VERSION ""

NS_ :

BS_:

BU_: DBG MASTER GPS MOTOR SENSOR APP

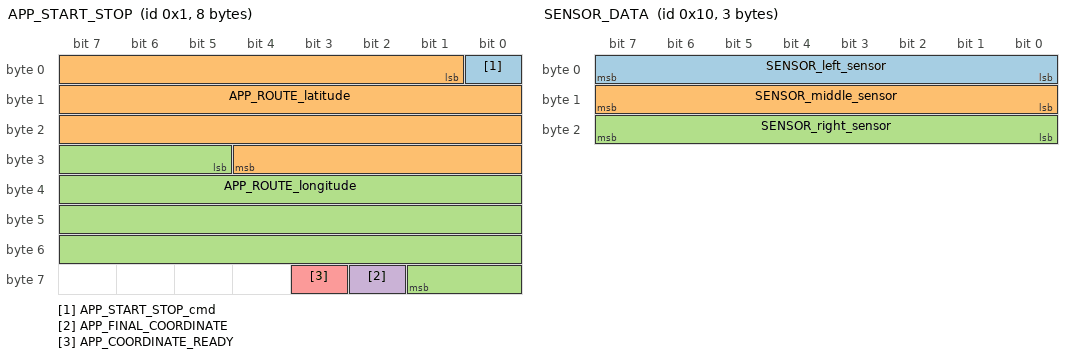
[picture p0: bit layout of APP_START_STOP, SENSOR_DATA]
BO_ 1 APP_START_STOP: 8 APP
 SG_ APP_START_STOP_cmd : 0|1@1+ (1,0) [0|0] "COMMAND" MASTER
 SG_ APP_ROUTE_latitude : 1|28@1+ (0.000001,-90.000000) [-90|90] "" MASTER
 SG_ APP_ROUTE_longitude : 29|29@1+ (0.000001,-180.000000) [-180|180] "" MASTER
 SG_ APP_FINAL_COORDINATE : 58|1@1+ (1,0) [0|0] "" MASTER
 SG_ APP_COORDINATE_READY : 59|1@1+ (1,0) [0|0] "" MASTER

BO_ 80 APP_ROUTE_DATA: 8 APP
 SG_ APP_READOUT_latitude : 0|28@1+ (0.000001,-90.000000) [-90|90] "" MASTER
 SG_ APP_READOUT_longitude : 28|29@1+ (0.000001,-180.000000) [-180|180] "" MASTER

BO_ 16 SENSOR_DATA: 3 SENSOR
 SG_ SENSOR_left_sensor : 0|8@1+ (1,0) [0|0] "Inches" MASTER,APP,MOTOR
 SG_ SENSOR_middle_sensor : 8|8@1+ (1,0) [0|0] "Inches" MASTER,APP,MOTOR
 SG_ SENSOR_right_sensor : 16|8@1+ (1,0) [0|0] "Inches" MASTER,APP,MOTOR

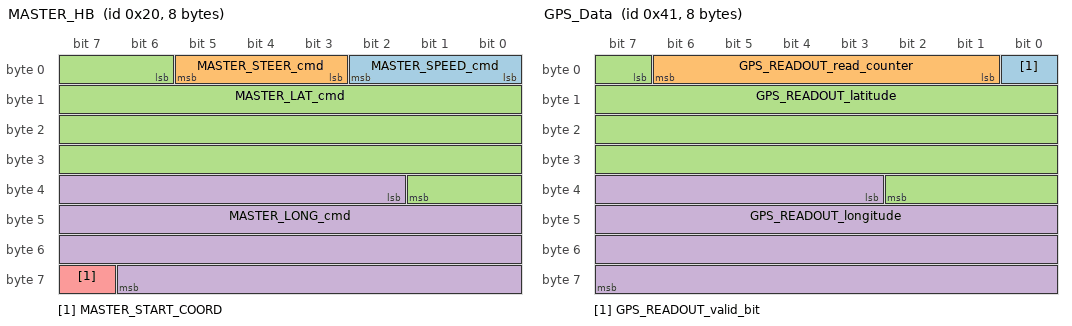
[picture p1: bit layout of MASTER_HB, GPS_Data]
BO_ 32 MASTER_HB: 8 MASTER
 SG_ MASTER_SPEED_cmd : 0|3@1+ (1,0) [0|0] "" SENSOR,MOTOR,GPS,APP
 SG_ MASTER_STEER_cmd : 3|3@1+ (1,0) [0|0] "" SENSOR,MOTOR,GPS,APP
 SG_ MASTER_LAT_cmd : 6|28@1+ (0.000001,-90.000000) [-90|90] "" SENSOR,MOTOR,GPS,APP
 SG_ MASTER_LONG_cmd : 34|29@1+ (0.000001,-180.000000) [-180|180] "" SENSOR,MOTOR,GPS,APP
 SG_ MASTER_START_COORD : 63|1@1+ (1,0) [0|0] "" SENSOR,MOTOR,GPS,APP

BO_ 65 GPS_Data: 8 GPS
 SG_ GPS_READOUT_valid_bit : 0|1@1+ (1,0) [0|1] "" MASTER,MOTOR,APP,MOTOR
 SG_ GPS_READOUT_read_counter : 1|6@1+ (1,0) [0|60] "" MASTER,MOTOR,APP
 SG_ GPS_READOUT_latitude : 7|28@1+ (0.000001,-90.000000) [-90|90] "" MASTER,MOTOR,APP
 SG_ GPS_READOUT_longitude : 35|29@1+ (0.000001,-180.000000) [-180|180] "" MASTER,MOTOR,APP

BO_ 66 COMPASS_Data: 2 GPS
 SG_ COMPASS_Heading : 0|9@1+ (1,0) [0|0] "DEGREE" MASTER,APP,MOTOR

BO_ 67 GEO_Header: 3 GPS
 SG_ GPS_ANGLE_degree : 0|12@1+ (0.1,-180) [-180.0|180.0] "Degree" MASTER,MOTOR,APP
 SG_ GPS_DISTANCE_meter : 12|12@1+ (0.1,0) [0.0|400.0] "Meters" MASTER,MOTOR,APP

BO_ 48 MOTOR_STATUS: 2 MOTOR
 SG_ MOTOR_STATUS_speed_mph : 0|16@1+ (0.001,0) [0|0] "mph" MASTER,APP

CM_ BU_ MASTER "The master controller driving the car";
CM_ BU_ MOTOR "The motor controller of the car";
CM_ BU_ SENSOR "The sensor controller of the car";
CM_ BU_ APP "The communication bridge controller of car";
CM_ BU_ GPS "GPS and compass controller of the car";
CM_ BO_ 100 "Sync message used to synchronize the controllers";

BA_DEF_ "BusType" STRING ;
BA_DEF_ BO_ "GenMsgCycleTime" INT 0 0;

BA_DEF_DEF_ "BusType" "CAN";
BA_DEF_DEF_ "GenMsgCycleTime" 0;

BA_ "GenMsgCycleTime" BO_ 32 100;
BA_ "GenMsgCycleTime" BO_ 16 100;
BA_ "GenMsgCycleTime" BO_ 48 100;
BA_ "GenMsgCycleTime" BO_ 65 100;
BA_ "GenMsgCycleTime" BO_ 66 100;
